# RA6M2 register map
Vendor: Renesas Electronics Corporation; Series: RA6; File version: 1.1
CPU: CM4 r0p1, little endian, MPU, FPU, VTOR, 4 interrupt priority bits
Registers are 8-bit, read-write, reset 0x0 unless marked. A register's access mark holds for its fields unless they carry their own. Offsets are from the block's base; [hi:lo] are bit positions; {n}, {i} and the like mark numbered series; 'fields as' and 'values as' point back to an identical list.

## GPT_OPS — Output Phase Switching Controller
Base 0x40078FF0
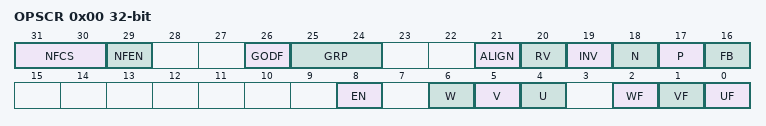
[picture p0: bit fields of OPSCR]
0x00 OPSCR 32-bit — Output Phase Switching Control Register
  [31:30] NFCS — External Input Noise Filter Clock selectionNoise filter sampling clock setting of the external input.
    0=PCLK/1; 1=PCLK/4; 2=PCLK/16; 3=PCLK/64
  [29] NFEN — External Input Noise Filter Enable
    0=Do not use a noise filter to the external input; 1=Use a noise filter to the external input
  [26] GODF — Group output disable function
    0=This bit function is ignored; 1=Group disable will clear OPSCR.EN Bit
  [25:24] GRP — Output disabled source selection
    0=Select Group A output disable source; 1=Select Group B output disable source; 2=Select Group C output disable source; 3=Select Group D output disable source
  [21] ALIGN — Input phase alignment
    0=Input phase is aligned to PCLK; 1=Input phase is aligned PWM
  [20] RV — Output phase rotation direction reversal
    0=U/V/W-Phase output; 1=Output to reverse the V / W-phase
  [19] INV — Invert-Phase Output Control
    0=Positive Logic (Active High)output; 1=Negative Logic (Active Low)output
  [18] N — Negative-Phase Output (N) Control
    0=Level signal output; 1=PWM signal output (PWM of GPT0)
  [17] P — Positive-Phase Output (P) Control
    0=Level signal output; 1=PWM signal output (PWM of GPT0)
  [16] FB — External Feedback Signal EnableThis bit selects the input phase from the software settings and external input.
    0=Select the external input; 1=Select the soft setting(OPSCR.UF, VF, WF)
  [8] EN — Enable-Phase Output Control
    0=Not Output(Hi-Z external terminals); 1=Output
  [6] W ro — Input W-Phase MonitorThis bit monitors the state of the input phase.OPSCR.FB=0:External input monitoring by PCLKOPSCR.FB=1:Software settings (UF/VF/WF)
  [5] V ro — Input V-Phase MonitorThis bit monitors the state of the input phase.OPSCR.FB=0:External input monitoring by PCLKOPSCR.FB=1:Software settings (UF/VF/WF)
  [4] U ro — Input U-Phase MonitorThis bit monitors the state of the input phase.OPSCR.FB=0:External input monitoring by PCLKOPSCR.FB=1:Software settings (UF/VF/WF)
  [2] WF — Input Phase Soft Setting UFThis bit sets the input phase by the software settings.This bit setting is valid when the OPSCR.FB bit = 1.
  [1] VF — Input Phase Soft Setting VFThis bit sets the input phase by the software settings.This bit setting is valid when the OPSCR.FB bit = 1.
  [0] UF — Input Phase Soft Setting WFThis bit sets the input phase by the software settings.This bit setting is valid when the OPSCR.FB bit = 1.

## POEG — Port Output Enable Module for GPT
Base 0x40042000
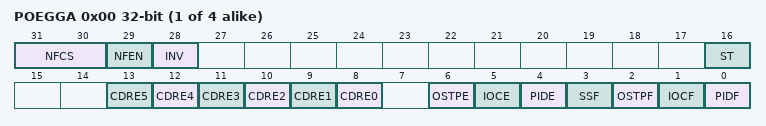
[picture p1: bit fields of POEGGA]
0x00 POEGG{x} (x=A,B,C,D; step 0x100) 32-bit — POEG Group {x} Setting Register
  [31:30] NFCS — Noise Filter Clock Select
    0=Sampling GTETRG pin input level for three times in every PCLKB; 1=Sampling GTETRG pin input level for three times in every PCLKB /8; 2=Sampling GTETRG pin input level for three times in every PCLKB /32; 3=Sampling GTETRG pin input level for three times in every PCLKB /128
  [29] NFEN — Noise Filter Enable
    0=Filtering noise disabled; 1=Filtering noise enabled
  [28] INV — GTETRG Input Reverse
    0=GTETRG Input; 1=GTETRG Input Reversed
  [16] ST ro — GTETRG Input Status Flag
    0=GTETRG input after filtering is 0; 1=GTETRG input after filtering is 1
  [n+8] CDRE{n} (n=0..5) — Comparator Disable Request Enable {n}Note: Can be modified only once after a reset.
    0=A disable request of comparator {n} disabled; 1=A disable request of comparator {n} enabled
  [6] OSTPE — Oscillation Stop Detection EnableNote: Can be modified only once after a reset.
    0=A output-disable request from the oscillation stop detection disabled; 1=A output-disable request from the oscillation stop detection enabled
  [5] IOCE — Enable for GPT Output-Disable RequestNote: Can be modified only once after a reset.
    0=Disable output-disable requests from GPT disable request; 1=Enable output-disable requests from GPT disable request
  [4] PIDE — Port Input Detection EnableNote: Can be modified only once after a reset.
    0=A output-disable request from the GTETRG pins disabled; 1=A output-disable request from the GTETRG pins enabled
  [3] SSF — Software Stop Flag
    0=A output-disable request from software has not been generated; 1=A output-disable request from software has been generated
  [2] OSTPF write-0-clears read-modifies — Oscillation Stop Detection Flag
    0=A output-disable request from the oscillation stop detection has not been generated; 1=A output-disable request from the oscillation stop detection has been generated
  [1] IOCF write-0-clears read-modifies — Real Time Overcurrent Detection Flag
    0=A output-disable request from GPT disable request or comparator interrupt has not been generated; 1=A output-disable request from GPT disable request or comparator interrupt has been generated
  [0] PIDF write-0-clears read-modifies — Port Input Detection Flag
    0=A output-disable request from the GTETRG pin has not been generated; 1=A output-disable request from the GTETRG pin has been generated

## GPT_ODC — PWM Delay Generation Circuit
Base 0x4007B000
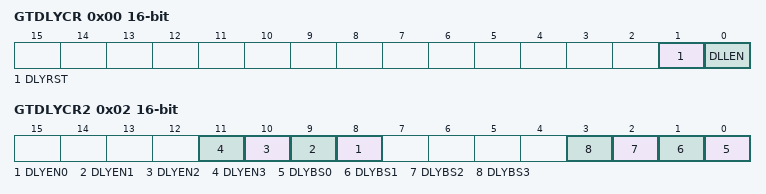
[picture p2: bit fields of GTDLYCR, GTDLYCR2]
0x00 GTDLYCR 16-bit — PWM Output Delay Control Register
  [1] DLYRST — PWM Delay Generation Circuit Reset
    0=Normal operation; 1=Reset
  [0] DLLEN — DLL Operation Enable
    0=Disable DLL operation; 1=Enable DLL operation
0x02 GTDLYCR2 16-bit — PWM Output Delay Control Register2
  [n+8] DLYEN{n} (n=0..3) — PWM Delay Generation Circuit enable for channel {n}
    0=Enable delay generation circuit of channel {n}; 1=Disable delay generation circuit of channel {n}
  [n] DLYBS{n} (n=0..3) — PWM Delay Generation Circuit bypass for channel {n}
    0=Bypass delay generation circuit of channel {n}; 1=Do not bypass delay generation circuit of channel {n}
{0x18+4i} GTDLYR{i}A (i=0..3) 16-bit (alternate view of GTDLYR{i}) — GTIOC{i}A Rising Output Delay Register
  [4:0] DLY — GTIOCnA Output Rising Edge Delay Setting
    0=No delay on rising edges; other=others (Delay of DLY/32 times the PCLKD period is applied.)
{0x1A+4i} GTDLYR{i}B (i=0..3) 16-bit (alternate view of GTDLYR{i}) — GTIOC{i}B Rising Output Delay Register
  [4:0] DLY — GTIOCnB Output Rising Edge Delay Setting
    values as GTDLYR0A.DLY
{0x28+4i} GTDLYF{i}A (i=0..3) 16-bit (alternate view of GTDLYF{i}) — GTIOC{i}A Falling Output Delay Register
  [4:0] DLY — GTIOCnA Output Falling Edge Delay Setting
    values as GTDLYR0A.DLY
{0x2A+4i} GTDLYF{i}B (i=0..3) 16-bit (alternate view of GTDLYF{i}) — GTIOC{i}B Falling Output Delay Register
  [4:0] DLY — GTIOCnB Output Falling Edge Delay Setting
    values as GTDLYR0A.DLY
